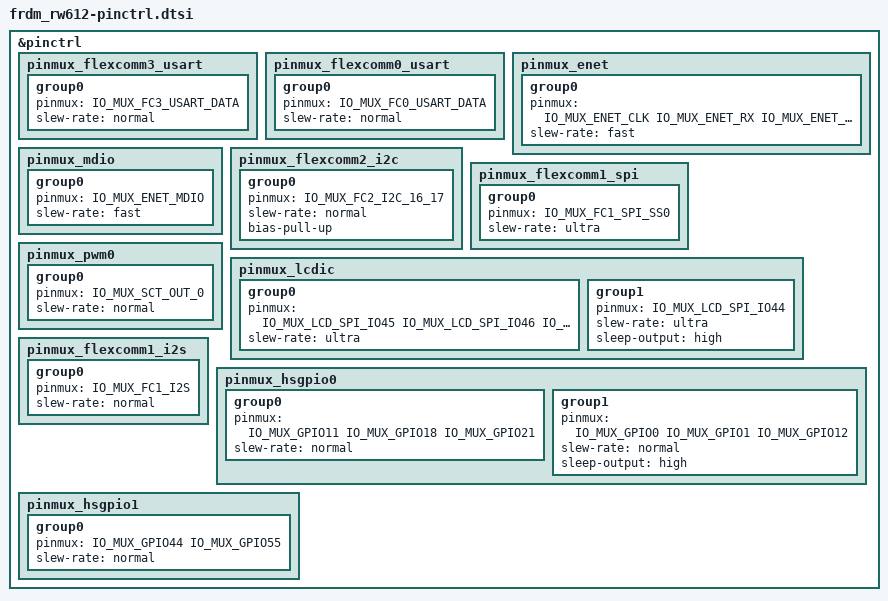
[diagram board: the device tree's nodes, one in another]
/*
 * Copyright 2022-2025 NXP
 *
 * SPDX-License-Identifier: Apache-2.0
 */

#include <nxp/rw/RW612-pinctrl.h>

&pinctrl {
	pinmux_flexcomm3_usart: pinmux_flexcomm3_usart {
		group0 {
			pinmux = <IO_MUX_FC3_USART_DATA>;
			slew-rate = "normal";
		};
	};

	pinmux_flexcomm0_usart: pinmux_flexcomm0_usart {
		group0 {
			pinmux = <IO_MUX_FC0_USART_DATA>;
			slew-rate = "normal";
		};
	};

	pinmux_enet: pinmux_enet {
		group0 {
			pinmux = <IO_MUX_ENET_CLK
				  IO_MUX_ENET_RX
				  IO_MUX_ENET_TX
				  IO_MUX_GPIO21
				  IO_MUX_GPIO55>;
			slew-rate = "fast";
		};
	};

	pinmux_mdio: pinmux_mdio {
		group0 {
			pinmux = <IO_MUX_ENET_MDIO>;
			slew-rate = "fast";
		};
	};

	pinmux_flexcomm2_i2c: pinmux_flexcomm2_i2c {
		group0 {
			pinmux = <IO_MUX_FC2_I2C_16_17>;
			slew-rate = "normal";
			bias-pull-up;
		};
	};

	pinmux_flexcomm1_spi: pinmux_flexcomm1_spi {
		group0 {
			pinmux = <IO_MUX_FC1_SPI_SS0>;
			slew-rate = "ultra";
		};
	};

	pinmux_pwm0: pinmux_pwm0 {
		group0 {
			pinmux = <IO_MUX_SCT_OUT_0>;
			slew-rate = "normal";
		};
	};

	pinmux_lcdic: pinmux_lcdic {
		group0 {
			pinmux = <IO_MUX_LCD_SPI_IO45
				  IO_MUX_LCD_SPI_IO46
				  IO_MUX_LCD_SPI_IO47
				  IO_MUX_LCD_SPI_IO48
				  IO_MUX_LCD_SPI_IO49>;
			slew-rate = "ultra";
		};

		group1 {
			pinmux = <IO_MUX_LCD_SPI_IO44>;
			slew-rate = "ultra";
			sleep-output = "high";
		};
	};

	pinmux_flexcomm1_i2s: pinmux_flexcomm1_i2s {
		group0 {
			pinmux = <IO_MUX_FC1_I2S>;
			slew-rate = "normal";
		};
	};

	pinmux_hsgpio0: pinmux_hsgpio0 {
		group0 {
			pinmux = <IO_MUX_GPIO11
				  IO_MUX_GPIO18
				  IO_MUX_GPIO21>;
			slew-rate = "normal";
		};

		group1 {
			pinmux = <IO_MUX_GPIO0
				  IO_MUX_GPIO1
				  IO_MUX_GPIO12>;
			slew-rate = "normal";
			sleep-output = "high";
		};
	};

	pinmux_hsgpio1: pinmux_hsgpio1 {
		group0 {
			pinmux = <IO_MUX_GPIO44
				  IO_MUX_GPIO55>;
			slew-rate = "normal";
		};
	};
};
